AUTOSAR XML (schema 314)
package /ComponentType
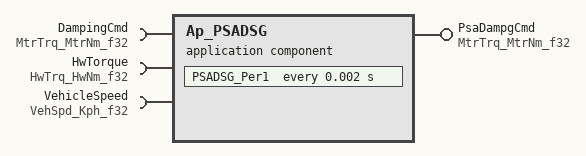
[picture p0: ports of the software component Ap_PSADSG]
  application software component type Ap_PSADSG
    provide port PsaDampgCmd: unqueued-sender-com-spec{data-element=MtrNm_f32, can-invalidate=false, init-value=D_ZERO_ULS_F32}, provided-interface=MtrTrq_MtrNm_f32
    require port DampingCmd: unqueued-receiver-com-spec{data-element=MtrNm_f32, init-value=D_ZERO_ULS_F32}, required-interface=MtrTrq_MtrNm_f32
    require port HwTorque: unqueued-receiver-com-spec{data-element=HwNm_f32, init-value=D_ZERO_ULS_F32}, required-interface=HwTrq_HwNm_f32
    require port VehicleSpeed: unqueued-receiver-com-spec{data-element=Kph_f32, init-value=D_ZERO_ULS_F32}, required-interface=VehSpd_Kph_f32
  internal behavior Ap_PSADSG_InternalBehavior: component=Ap_PSADSG
    timing event TMT_PSADSG_Per1: start-on-event=PSADSG_Per1, period=0.002
    port-api-options:
      enable-take-address=false, indirect-api=false, port=DampingCmd
      enable-take-address=false, indirect-api=false, port=HwTorque
      enable-take-address=false, indirect-api=false, port=PsaDampgCmd
      enable-take-address=false, indirect-api=false, port=VehicleSpeed
    runnable PSADSG_Per1  # PSADSG_Per1 should be called after Dampg_Per1 (SF003A periodic) and before DampgFwl_Per1 (SF035A periodic).
      data read access READ_DampingCmd_MtrNm_f32: data-element=DampingCmd.MtrNm_f32
      data read access READ_HwTorque_HwNm_f32: data-element=HwTorque.HwNm_f32
      data read access READ_VehicleSpeed_Kph_f32: data-element=VehicleSpeed.Kph_f32
      data write access WRITE_PsaDampgCmd_MtrNm_f32: data-element=PsaDampgCmd.MtrNm_f32
  swc implementation Ap_PSADSG_Implementation: behavior=Ap_PSADSG_InternalBehavior
    code-descriptors:
      code Code: type=SRC
